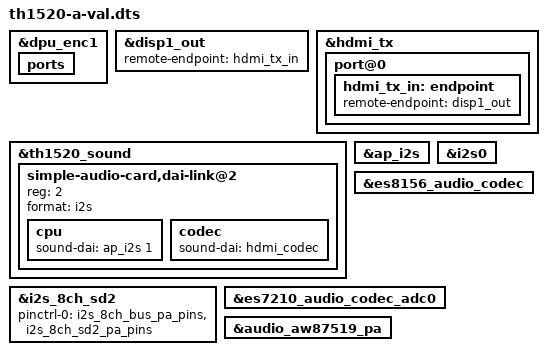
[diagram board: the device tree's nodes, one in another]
// SPDX-License-Identifier: (GPL-2.0 OR MIT)
/*
 * Copyright (C) 2021-2024 Alibaba Group Holding Limited.
 */

#include "th1520-a-val.dtsi"

&dpu_enc1 {
	ports {
		/delete-node/ port@0;
	};
};

&disp1_out {
	remote-endpoint = <&hdmi_tx_in>;
};

&hdmi_tx {
	status = "okay";

	port@0 {
		/* input */
		hdmi_tx_in: endpoint {
			remote-endpoint = <&disp1_out>;
		};
	};
};

&th1520_sound {
    status = "okay";

    simple-audio-card,dai-link@2 {          /* I2S - HDMI */
        reg = <2>;
        format = "i2s";
        cpu {
            sound-dai = <&ap_i2s 1>;
        };
        codec {
            sound-dai = <&hdmi_codec>;
        };
    };
};

&ap_i2s {
	status = "okay";
};

&i2s0 {
	status = "okay";
};

&i2s_8ch_sd2 {
	status = "okay";
	pinctrl-names = "default";
	pinctrl-0 = <&i2s_8ch_bus_pa_pins>,
				<&i2s_8ch_sd2_pa_pins>;
};

&es8156_audio_codec {
	status = "okay";
};

&es7210_audio_codec_adc0 {
	status = "okay";
};

&audio_aw87519_pa {
	status = "okay";
};
